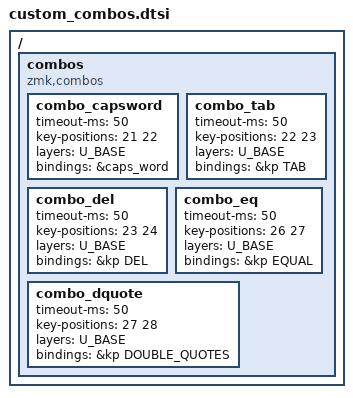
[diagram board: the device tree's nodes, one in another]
/ {
    combos {
        compatible = "zmk,combos";
        combo_capsword {
            timeout-ms = 50;
            key-positions = 21 22;
            layers = U_BASE;
            bindings = &caps_word;
        };
        combo_tab {
            timeout-ms = 50;
            key-positions = 22 23;
            layers = U_BASE;
            bindings = &kp TAB;
        };
        combo_del {
            timeout-ms = 50;
            key-positions = 23 24;
            layers = U_BASE;
            bindings = &kp DEL;
        };
        combo_eq {
            timeout-ms = 50;
            key-positions = 26 27;
            layers = U_BASE;
            bindings = &kp EQUAL;
        };
        combo_dquote {
            timeout-ms = 50;
            key-positions = 27 28;
            layers = U_BASE;
            bindings = &kp DOUBLE_QUOTES;
        };
    };
};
